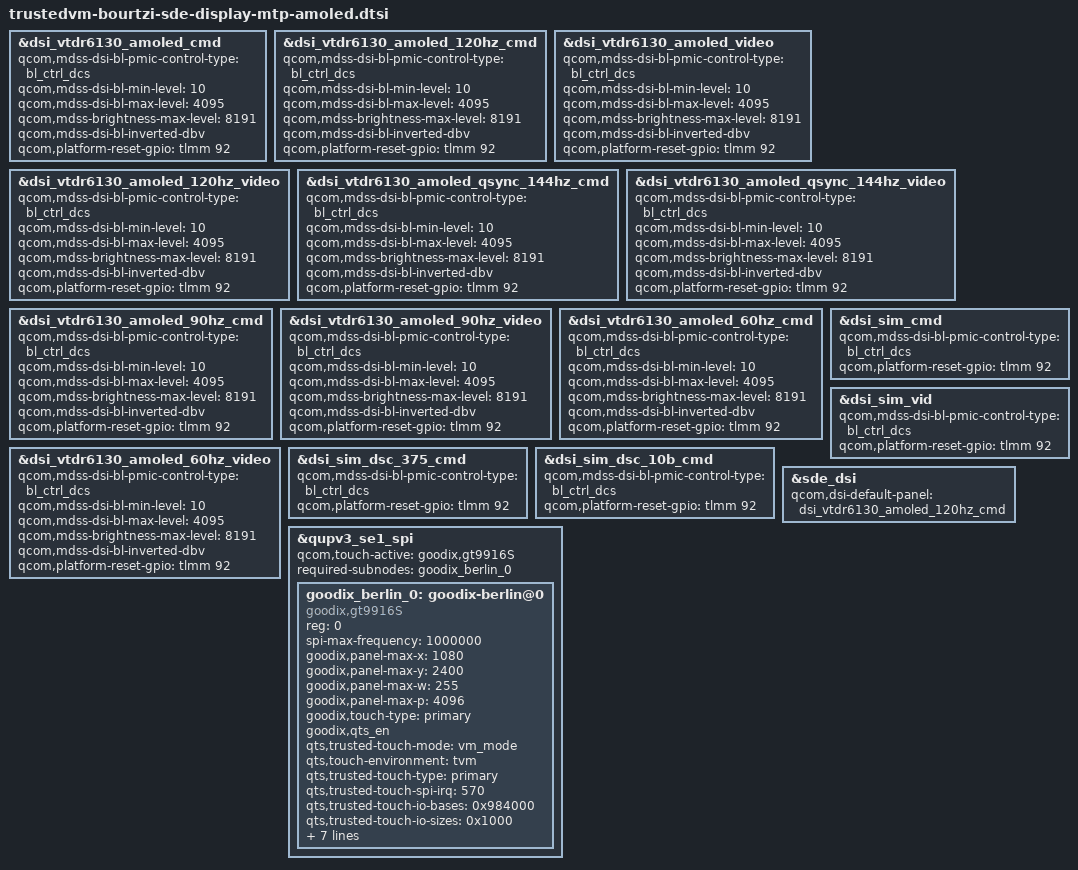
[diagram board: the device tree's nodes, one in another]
// SPDX-License-Identifier: BSD-3-Clause
/*
 * Copyright (c) Qualcomm Technologies, Inc. and/or its subsidiaries.
 */

#include "trustedvm-bourtzi-sde-display.dtsi"

&dsi_vtdr6130_amoled_cmd {
	qcom,mdss-dsi-bl-pmic-control-type = "bl_ctrl_dcs";
	qcom,mdss-dsi-bl-min-level = <10>;
	qcom,mdss-dsi-bl-max-level = <4095>;
	qcom,mdss-brightness-max-level = <8191>;
	qcom,mdss-dsi-bl-inverted-dbv;
	qcom,platform-reset-gpio = <&tlmm 92 0>;
};

&dsi_vtdr6130_amoled_120hz_cmd {
	qcom,mdss-dsi-bl-pmic-control-type = "bl_ctrl_dcs";
	qcom,mdss-dsi-bl-min-level = <10>;
	qcom,mdss-dsi-bl-max-level = <4095>;
	qcom,mdss-brightness-max-level = <8191>;
	qcom,mdss-dsi-bl-inverted-dbv;
	qcom,platform-reset-gpio = <&tlmm 92 0>;
};

&dsi_vtdr6130_amoled_video {
	qcom,mdss-dsi-bl-pmic-control-type = "bl_ctrl_dcs";
	qcom,mdss-dsi-bl-min-level = <10>;
	qcom,mdss-dsi-bl-max-level = <4095>;
	qcom,mdss-brightness-max-level = <8191>;
	qcom,mdss-dsi-bl-inverted-dbv;
	qcom,platform-reset-gpio = <&tlmm 92 0>;
};

&dsi_vtdr6130_amoled_120hz_video {
	qcom,mdss-dsi-bl-pmic-control-type = "bl_ctrl_dcs";
	qcom,mdss-dsi-bl-min-level = <10>;
	qcom,mdss-dsi-bl-max-level = <4095>;
	qcom,mdss-brightness-max-level = <8191>;
	qcom,mdss-dsi-bl-inverted-dbv;
	qcom,platform-reset-gpio = <&tlmm 92 0>;
};

&dsi_vtdr6130_amoled_qsync_144hz_cmd {
	qcom,mdss-dsi-bl-pmic-control-type = "bl_ctrl_dcs";
	qcom,mdss-dsi-bl-min-level = <10>;
	qcom,mdss-dsi-bl-max-level = <4095>;
	qcom,mdss-brightness-max-level = <8191>;
	qcom,mdss-dsi-bl-inverted-dbv;
	qcom,platform-reset-gpio = <&tlmm 92 0>;
};

&dsi_vtdr6130_amoled_qsync_144hz_video {
	qcom,mdss-dsi-bl-pmic-control-type = "bl_ctrl_dcs";
	qcom,mdss-dsi-bl-min-level = <10>;
	qcom,mdss-dsi-bl-max-level = <4095>;
	qcom,mdss-brightness-max-level = <8191>;
	qcom,mdss-dsi-bl-inverted-dbv;
	qcom,platform-reset-gpio = <&tlmm 92 0>;
};

&dsi_vtdr6130_amoled_90hz_cmd {
	qcom,mdss-dsi-bl-pmic-control-type = "bl_ctrl_dcs";
	qcom,mdss-dsi-bl-min-level = <10>;
	qcom,mdss-dsi-bl-max-level = <4095>;
	qcom,mdss-brightness-max-level = <8191>;
	qcom,mdss-dsi-bl-inverted-dbv;
	qcom,platform-reset-gpio = <&tlmm 92 0>;
};

&dsi_vtdr6130_amoled_90hz_video {
	qcom,mdss-dsi-bl-pmic-control-type = "bl_ctrl_dcs";
	qcom,mdss-dsi-bl-min-level = <10>;
	qcom,mdss-dsi-bl-max-level = <4095>;
	qcom,mdss-brightness-max-level = <8191>;
	qcom,mdss-dsi-bl-inverted-dbv;
	qcom,platform-reset-gpio = <&tlmm 92 0>;
};

&dsi_vtdr6130_amoled_60hz_cmd {
	qcom,mdss-dsi-bl-pmic-control-type = "bl_ctrl_dcs";
	qcom,mdss-dsi-bl-min-level = <10>;
	qcom,mdss-dsi-bl-max-level = <4095>;
	qcom,mdss-brightness-max-level = <8191>;
	qcom,mdss-dsi-bl-inverted-dbv;
	qcom,platform-reset-gpio = <&tlmm 92 0>;
};

&dsi_vtdr6130_amoled_60hz_video {
	qcom,mdss-dsi-bl-pmic-control-type = "bl_ctrl_dcs";
	qcom,mdss-dsi-bl-min-level = <10>;
	qcom,mdss-dsi-bl-max-level = <4095>;
	qcom,mdss-brightness-max-level = <8191>;
	qcom,mdss-dsi-bl-inverted-dbv;
	qcom,platform-reset-gpio = <&tlmm 92 0>;
};

&dsi_sim_cmd {
	qcom,mdss-dsi-bl-pmic-control-type = "bl_ctrl_dcs";
	qcom,platform-reset-gpio = <&tlmm 92 0>;
};

&dsi_sim_vid {
	qcom,mdss-dsi-bl-pmic-control-type = "bl_ctrl_dcs";
	qcom,platform-reset-gpio = <&tlmm 92 0>;
};

&dsi_sim_dsc_375_cmd {
	qcom,mdss-dsi-bl-pmic-control-type = "bl_ctrl_dcs";
	qcom,platform-reset-gpio = <&tlmm 92 0>;
};

&dsi_sim_dsc_10b_cmd {
	qcom,mdss-dsi-bl-pmic-control-type = "bl_ctrl_dcs";
	qcom,platform-reset-gpio = <&tlmm 92 0>;
};

&sde_dsi {
	qcom,dsi-default-panel = <&dsi_vtdr6130_amoled_120hz_cmd>;
};

&qupv3_se1_spi {
	#address-cells = <1>;
	#size-cells = <0>;
	status = "ok";

	qcom,touch-active = "goodix,gt9916S";
	required-subnodes = <&goodix_berlin_0>;

	goodix_berlin_0: goodix-berlin@0 {
		compatible = "goodix,gt9916S";
		reg = <0>;
		spi-max-frequency = <1000000>;
		goodix,panel-max-x = <1080>;
		goodix,panel-max-y = <2400>;
		goodix,panel-max-w = <255>;
		goodix,panel-max-p = <4096>;

		goodix,touch-type = "primary";
		goodix,qts_en;
		qts,trusted-touch-mode = "vm_mode";
		qts,touch-environment = "tvm";
		qts,trusted-touch-type = "primary";
		qts,trusted-touch-spi-irq = <570>;
		qts,trusted-touch-io-bases = <0x984000>;
		qts,trusted-touch-io-sizes = <0x1000>;
		qts,trusted-touch-vm-gpio-list = <&tlmm 10 0 &tlmm 11 0 &tlmm 12 0
						&tlmm 13 0 &tlmm 95 0 &tlmm 105 0x2008>;
		panel = <&dsi_vtdr6130_amoled_cmd
			&dsi_vtdr6130_amoled_120hz_cmd
			&dsi_vtdr6130_amoled_video
			&dsi_vtdr6130_amoled_120hz_video>;

	};
};
